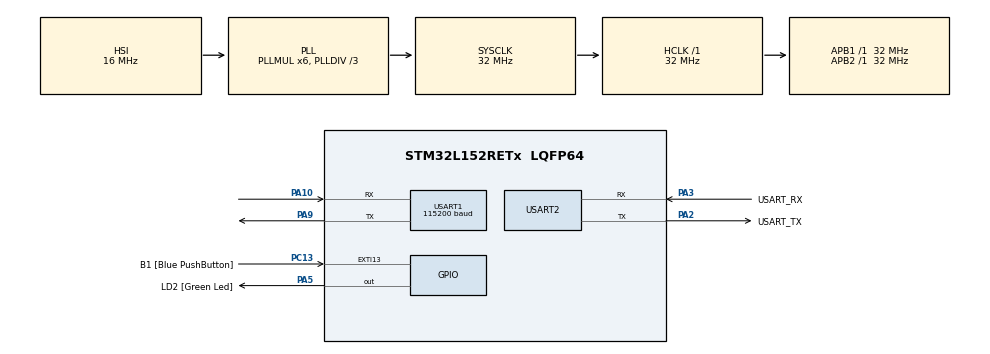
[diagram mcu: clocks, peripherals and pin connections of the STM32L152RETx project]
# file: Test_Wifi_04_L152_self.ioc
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Mcu.Family=STM32L1
Mcu.Name=STM32L152RETx
Mcu.Package=LQFP64
NVIC.PriorityGroup=NVIC_PRIORITYGROUP_4
NVIC.TIM2_IRQn=true\:15\:0\:false\:false\:true\:false\:true\:true
NVIC.TimeBase=TIM2_IRQn
NVIC.TimeBaseIP=TIM2
NVIC.USART1_IRQn=true\:0\:0\:false\:false\:true\:true\:true\:true
PA10.Mode=Asynchronous
PA10.Signal=USART1_RX
PA13.GPIO_Label=TMS
PA13.Mode=Serial_Wire
PA13.Signal=SYS_JTMS-SWDIO
PA14.GPIO_Label=TCK
PA14.Mode=Serial_Wire
PA14.Signal=SYS_JTCK-SWCLK
PA2.GPIO_Label=USART_TX
PA2.Mode=Asynchronous
PA2.Signal=USART2_TX
PA3.GPIO_Label=USART_RX
PA3.Mode=Asynchronous
PA3.Signal=USART2_RX
PA5.GPIO_Label=LD2 [Green Led]
PA5.Signal=GPIO_Output
PA9.Mode=Asynchronous
PA9.Signal=USART1_TX
PB3.GPIO_Label=SWO
PB3.Signal=SYS_JTDO-TRACESWO
PC13-WKUP2.GPIO_Label=B1 [Blue PushButton]
PC13-WKUP2.Signal=GPXTI13
PC14-OSC32_IN.Mode=LSE-External-Oscillator
PC14-OSC32_IN.Signal=RCC_OSC32_IN
PC15-OSC32_OUT.Mode=LSE-External-Oscillator
PC15-OSC32_OUT.Signal=RCC_OSC32_OUT
PH0-OSC_IN.Mode=HSE-External-Clock-Source
PH0-OSC_IN.Signal=RCC_OSC_IN
PH1-OSC_OUT.Signal=RCC_OSC_OUT
ProjectManager.HeapSize=0x200
ProjectManager.StackSize=0x400
ProjectManager.TargetToolchain=STM32CubeIDE
RCC.48MHZClocksFreq_Value=48000000
RCC.AHBFreq_Value=32000000
RCC.APB1Freq_Value=32000000
RCC.APB1TimFreq_Value=32000000
RCC.APB2Freq_Value=32000000
RCC.APB2TimFreq_Value=32000000
RCC.HCLKFreq_Value=32000000
RCC.HSE_VALUE=8000000
RCC.HSI_VALUE=16000000
RCC.MSI_VALUE=2097000
RCC.PLLDIV=RCC_PLL_DIV3
RCC.PLLMUL=RCC_PLL_MUL6
RCC.RTCClockSelectionVirtual=RCC_RTCCLKSOURCE_LSE
RCC.SYSCLKFreq_VALUE=32000000
RCC.SYSCLKSource=RCC_SYSCLKSOURCE_PLLCLK
RCC.USBOutput=48000000
RCC.VCOOutputFreq_Value=96000000
USART1.BaudRate=115200
USART1.Parity=PARITY_NONE
USART1.VirtualMode=VM_ASYNC
USART2.VirtualMode=VM_ASYNC
VP_SYS_VS_tim2.Mode=TIM2
board=NUCLEO-L152RE

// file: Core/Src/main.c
/* USER CODE BEGIN Header */
/**
  ******************************************************************************
  * @file           : main.c
  * @brief          : Main program body
  ******************************************************************************
  * @attention
  *
  * Copyright (c) 2023 STMicroelectronics.
  * All rights reserved.
  *
  * This software is licensed under terms that can be found in the LICENSE file
  * in the root directory of this software component.
  * If no LICENSE file comes with this software, it is provided AS-IS.
  *
  ******************************************************************************
  */
/* USER CODE END Header */
#include "main.h"
#include "usart.h"
#include "gpio.h"

/* USER CODE BEGIN Includes */
#include "stdlib.h"
#include "stdio.h"
#include "string.h"
#include "wifi.h"
/* USER CODE END Includes */

void SystemClock_Config(void);
/* USER CODE BEGIN PFP */
int _write(int file, char *ptr, int len);
/* USER CODE END PFP */

/* USER CODE BEGIN 0 */
int _write(int file, char *ptr, int len)
{
int DataIdx;
for (DataIdx = 0; DataIdx < len; DataIdx++)
{
//__io_putchar(*ptr++);
ITM_SendChar(*ptr++);
}
return len;
}
/* USER CODE END 0 */

int main(void)
{

  /* MCU Configuration--------------------------------------------------------*/

  /* Reset of all peripherals, Initializes the Flash interface and the Systick. */
  HAL_Init();

  /* Configure the system clock */
  SystemClock_Config();

  /* Initialize all configured peripherals */
  MX_GPIO_Init();
  MX_USART2_UART_Init();
  MX_USART1_UART_Init();
  /* USER CODE BEGIN 2 */
  Wifi_Init();
  /* USER CODE END 2 */

  /* Infinite loop */
  while (1)
  {

    /* USER CODE BEGIN 3 */
	  Wifi_Process();
  }
  /* USER CODE END 3 */
}

void SystemClock_Config(void)
{
  RCC_OscInitTypeDef RCC_OscInitStruct = {0};
  RCC_ClkInitTypeDef RCC_ClkInitStruct = {0};

  /** Configure the main internal regulator output voltage
  */
  __HAL_PWR_VOLTAGESCALING_CONFIG(PWR_REGULATOR_VOLTAGE_SCALE1);

  /** Initializes the RCC Oscillators according to the specified parameters
  * in the RCC_OscInitTypeDef structure.
  */
  RCC_OscInitStruct.OscillatorType = RCC_OSCILLATORTYPE_HSI;
  RCC_OscInitStruct.HSIState = RCC_HSI_ON;
  RCC_OscInitStruct.HSICalibrationValue = RCC_HSICALIBRATION_DEFAULT;
  RCC_OscInitStruct.PLL.PLLState = RCC_PLL_ON;
  RCC_OscInitStruct.PLL.PLLSource = RCC_PLLSOURCE_HSI;
  RCC_OscInitStruct.PLL.PLLMUL = RCC_PLL_MUL6;
  RCC_OscInitStruct.PLL.PLLDIV = RCC_PLL_DIV3;
  if (HAL_RCC_OscConfig(&RCC_OscInitStruct) != HAL_OK)
  {
    Error_Handler();
  }

  /** Initializes the CPU, AHB and APB buses clocks
  */
  RCC_ClkInitStruct.ClockType = RCC_CLOCKTYPE_HCLK|RCC_CLOCKTYPE_SYSCLK
                              |RCC_CLOCKTYPE_PCLK1|RCC_CLOCKTYPE_PCLK2;
  RCC_ClkInitStruct.SYSCLKSource = RCC_SYSCLKSOURCE_PLLCLK;
  RCC_ClkInitStruct.AHBCLKDivider = RCC_SYSCLK_DIV1;
  RCC_ClkInitStruct.APB1CLKDivider = RCC_HCLK_DIV1;
  RCC_ClkInitStruct.APB2CLKDivider = RCC_HCLK_DIV1;

  if (HAL_RCC_ClockConfig(&RCC_ClkInitStruct, FLASH_LATENCY_1) != HAL_OK)
  {
    Error_Handler();
  }
}

void HAL_TIM_PeriodElapsedCallback(TIM_HandleTypeDef *htim)
{
  if (htim->Instance == TIM2) {
    HAL_IncTick();
  }
}

void Error_Handler(void)
{
  __disable_irq();
  while (1)
  {
  }
}
